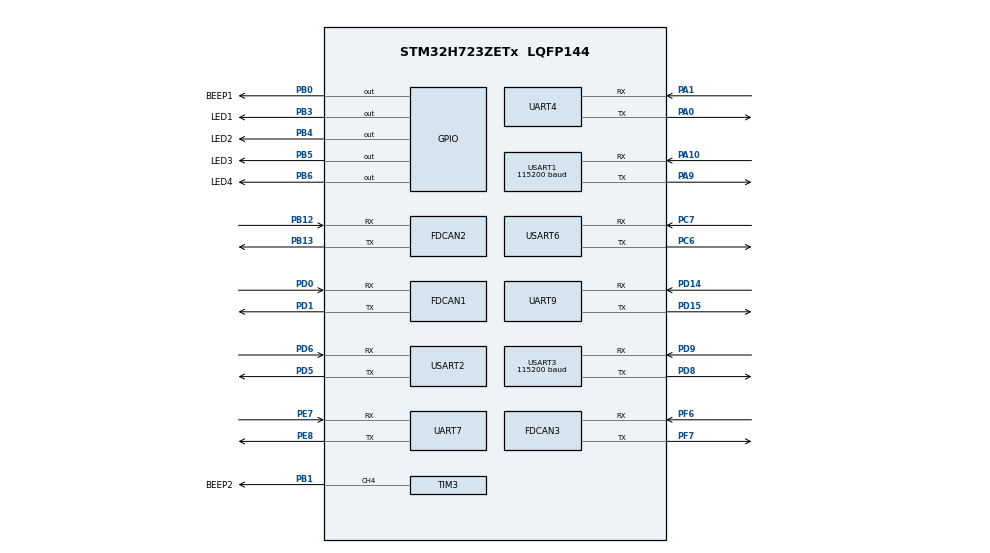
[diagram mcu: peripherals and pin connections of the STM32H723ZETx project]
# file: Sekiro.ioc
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CORTEX_M7.AccessPermission_S-Cortex_Memory_Protection_Unit_Region1_Settings_S=MPU_REGION_PRIV_RO
CORTEX_M7.AccessPermission_S-Cortex_Memory_Protection_Unit_Region2_Settings_S=MPU_REGION_FULL_ACCESS
CORTEX_M7.AccessPermission_Spec=MPU_REGION_FULL_ACCESS
CORTEX_M7.BaseAddress_S-Cortex_Memory_Protection_Unit_Region1_Settings_S=0x08000000
CORTEX_M7.BaseAddress_S-Cortex_Memory_Protection_Unit_Region2_Settings_S=0x30000000
CORTEX_M7.BaseAddress_Spec=0x24000000
CORTEX_M7.CPU_DCache=Enabled
CORTEX_M7.CPU_ICache=Enabled
CORTEX_M7.DisableExec_Spec=MPU_INSTRUCTION_ACCESS_ENABLE
CORTEX_M7.Enable_S-Cortex_Memory_Protection_Unit_Region1_Settings_S=MPU_REGION_ENABLE
CORTEX_M7.Enable_S-Cortex_Memory_Protection_Unit_Region2_Settings_S=MPU_REGION_ENABLE
CORTEX_M7.IsBufferable_Spec=MPU_ACCESS_BUFFERABLE
CORTEX_M7.IsCacheable_S-Cortex_Memory_Protection_Unit_Region1_Settings_S=MPU_ACCESS_CACHEABLE
CORTEX_M7.IsCacheable_S-Cortex_Memory_Protection_Unit_Region2_Settings_S=MPU_ACCESS_CACHEABLE
CORTEX_M7.IsCacheable_Spec=MPU_ACCESS_CACHEABLE
CORTEX_M7.IsShareable_Spec=MPU_ACCESS_NOT_SHAREABLE
CORTEX_M7.Number_S-Cortex_Memory_Protection_Unit_Region2_Settings_S=MPU_REGION_NUMBER2
CORTEX_M7.Number_S-Cortex_Memory_Protection_Unit_Region3_Settings_S=MPU_REGION_NUMBER3
CORTEX_M7.Number_S-Cortex_Memory_Protection_Unit_Region4_Settings_S=MPU_REGION_NUMBER4
CORTEX_M7.Size_S-Cortex_Memory_Protection_Unit_Region1_Settings_S=MPU_REGION_SIZE_512KB
CORTEX_M7.Size_S-Cortex_Memory_Protection_Unit_Region2_Settings_S=MPU_REGION_SIZE_512MB
CORTEX_M7.Size_Spec=MPU_REGION_SIZE_128KB
CORTEX_M7.SubRegionDisable_S-Cortex_Memory_Protection_Unit_Region2_Settings_S=0xFA
CORTEX_M7.SubRegionDisable_Spec=0
CORTEX_M7.TypeExtField_Spec=MPU_TEX_LEVEL1
CORTEX_M7.default_mode_Activation=1
Dma.Request0=USART3_RX
Dma.Request1=USART3_TX
Dma.Request2=USART2_RX
Dma.Request3=USART2_TX
Dma.Request4=USART6_RX
Dma.Request5=USART6_TX
Dma.Request6=USART1_RX
Dma.Request7=USART1_TX
Dma.Request8=UART9_TX
Dma.Request9=UART9_RX
Dma.UART9_RX.9.Direction=DMA_PERIPH_TO_MEMORY
Dma.UART9_RX.9.EventEnable=DISABLE
Dma.UART9_RX.9.FIFOMode=DMA_FIFOMODE_DISABLE
Dma.UART9_RX.9.Instance=DMA2_Stream1
Dma.UART9_RX.9.MemDataAlignment=DMA_MDATAALIGN_BYTE
Dma.UART9_RX.9.MemInc=DMA_MINC_ENABLE
Dma.UART9_RX.9.Mode=DMA_NORMAL
Dma.UART9_RX.9.PeriphDataAlignment=DMA_PDATAALIGN_BYTE
Dma.UART9_RX.9.PeriphInc=DMA_PINC_DISABLE
Dma.UART9_RX.9.Polarity=HAL_DMAMUX_REQ_GEN_RISING
Dma.UART9_RX.9.Priority=DMA_PRIORITY_VERY_HIGH
Dma.UART9_RX.9.RequestNumber=1
Dma.UART9_RX.9.SignalID=NONE
Dma.UART9_RX.9.SyncEnable=DISABLE
Dma.UART9_RX.9.SyncPolarity=HAL_DMAMUX_SYNC_NO_EVENT
Dma.UART9_RX.9.SyncRequestNumber=1
Dma.UART9_RX.9.SyncSignalID=NONE
Dma.UART9_TX.8.Direction=DMA_MEMORY_TO_PERIPH
Dma.UART9_TX.8.EventEnable=DISABLE
Dma.UART9_TX.8.FIFOMode=DMA_FIFOMODE_DISABLE
Dma.UART9_TX.8.Instance=DMA2_Stream0
Dma.UART9_TX.8.MemDataAlignment=DMA_MDATAALIGN_BYTE
Dma.UART9_TX.8.MemInc=DMA_MINC_ENABLE
Dma.UART9_TX.8.Mode=DMA_NORMAL
Dma.UART9_TX.8.PeriphDataAlignment=DMA_PDATAALIGN_BYTE
Dma.UART9_TX.8.PeriphInc=DMA_PINC_DISABLE
Dma.UART9_TX.8.Polarity=HAL_DMAMUX_REQ_GEN_RISING
Dma.UART9_TX.8.Priority=DMA_PRIORITY_VERY_HIGH
Dma.UART9_TX.8.RequestNumber=1
Dma.UART9_TX.8.SignalID=NONE
Dma.UART9_TX.8.SyncEnable=DISABLE
Dma.UART9_TX.8.SyncPolarity=HAL_DMAMUX_SYNC_NO_EVENT
Dma.UART9_TX.8.SyncRequestNumber=1
Dma.UART9_TX.8.SyncSignalID=NONE
Dma.USART1_RX.6.Direction=DMA_PERIPH_TO_MEMORY
Dma.USART1_RX.6.EventEnable=DISABLE
Dma.USART1_RX.6.FIFOMode=DMA_FIFOMODE_DISABLE
Dma.USART1_RX.6.Instance=DMA1_Stream4
Dma.USART1_RX.6.MemDataAlignment=DMA_MDATAALIGN_BYTE
Dma.USART1_RX.6.MemInc=DMA_MINC_ENABLE
Dma.USART1_RX.6.Mode=DMA_CIRCULAR
Dma.USART1_RX.6.PeriphDataAlignment=DMA_PDATAALIGN_BYTE
Dma.USART1_RX.6.PeriphInc=DMA_PINC_DISABLE
Dma.USART1_RX.6.Polarity=HAL_DMAMUX_REQ_GEN_RISING
Dma.USART1_RX.6.Priority=DMA_PRIORITY_VERY_HIGH
Dma.USART1_RX.6.RequestNumber=1
Dma.USART1_RX.6.SignalID=NONE
Dma.USART1_RX.6.SyncEnable=DISABLE
Dma.USART1_RX.6.SyncPolarity=HAL_DMAMUX_SYNC_NO_EVENT
Dma.USART1_RX.6.SyncRequestNumber=1
Dma.USART1_RX.6.SyncSignalID=NONE
Dma.USART1_TX.7.Direction=DMA_MEMORY_TO_PERIPH
Dma.USART1_TX.7.EventEnable=DISABLE
Dma.USART1_TX.7.FIFOMode=DMA_FIFOMODE_DISABLE
Dma.USART1_TX.7.Instance=DMA1_Stream5
Dma.USART1_TX.7.MemDataAlignment=DMA_MDATAALIGN_BYTE
Dma.USART1_TX.7.MemInc=DMA_MINC_ENABLE
Dma.USART1_TX.7.Mode=DMA_NORMAL
Dma.USART1_TX.7.PeriphDataAlignment=DMA_PDATAALIGN_BYTE
Dma.USART1_TX.7.PeriphInc=DMA_PINC_DISABLE
Dma.USART1_TX.7.Polarity=HAL_DMAMUX_REQ_GEN_RISING
Dma.USART1_TX.7.Priority=DMA_PRIORITY_VERY_HIGH
Dma.USART1_TX.7.RequestNumber=1
Dma.USART1_TX.7.SignalID=NONE
Dma.USART1_TX.7.SyncEnable=DISABLE
Dma.USART1_TX.7.SyncPolarity=HAL_DMAMUX_SYNC_NO_EVENT
Dma.USART1_TX.7.SyncRequestNumber=1
Dma.USART1_TX.7.SyncSignalID=NONE
Dma.USART2_RX.2.Direction=DMA_PERIPH_TO_MEMORY
Dma.USART2_RX.2.EventEnable=DISABLE
Dma.USART2_RX.2.FIFOMode=DMA_FIFOMODE_DISABLE
Dma.USART2_RX.2.Instance=DMA1_Stream2
Dma.USART2_RX.2.MemDataAlignment=DMA_MDATAALIGN_BYTE
Dma.USART2_RX.2.MemInc=DMA_MINC_ENABLE
Dma.USART2_RX.2.Mode=DMA_NORMAL
Dma.USART2_RX.2.PeriphDataAlignment=DMA_PDATAALIGN_BYTE
Dma.USART2_RX.2.PeriphInc=DMA_PINC_DISABLE
Dma.USART2_RX.2.Polarity=HAL_DMAMUX_REQ_GEN_RISING
Dma.USART2_RX.2.Priority=DMA_PRIORITY_VERY_HIGH
Dma.USART2_RX.2.RequestNumber=1
Dma.USART2_RX.2.SignalID=NONE
Dma.USART2_RX.2.SyncEnable=DISABLE
Dma.USART2_RX.2.SyncPolarity=HAL_DMAMUX_SYNC_NO_EVENT
Dma.USART2_RX.2.SyncRequestNumber=1
Dma.USART2_RX.2.SyncSignalID=NONE
Dma.USART2_TX.3.Direction=DMA_MEMORY_TO_PERIPH
Dma.USART2_TX.3.EventEnable=DISABLE
Dma.USART2_TX.3.FIFOMode=DMA_FIFOMODE_DISABLE
Dma.USART2_TX.3.Instance=DMA1_Stream3
Dma.USART2_TX.3.MemDataAlignment=DMA_MDATAALIGN_BYTE
Dma.USART2_TX.3.MemInc=DMA_MINC_ENABLE
Dma.USART2_TX.3.Mode=DMA_NORMAL
Dma.USART2_TX.3.PeriphDataAlignment=DMA_PDATAALIGN_BYTE
Dma.USART2_TX.3.PeriphInc=DMA_PINC_DISABLE
Dma.USART2_TX.3.Polarity=HAL_DMAMUX_REQ_GEN_RISING
Dma.USART2_TX.3.Priority=DMA_PRIORITY_VERY_HIGH
Dma.USART2_TX.3.RequestNumber=1
Dma.USART2_TX.3.SignalID=NONE
Dma.USART2_TX.3.SyncEnable=DISABLE
Dma.USART2_TX.3.SyncPolarity=HAL_DMAMUX_SYNC_NO_EVENT
Dma.USART2_TX.3.SyncRequestNumber=1
Dma.USART2_TX.3.SyncSignalID=NONE
Dma.USART3_RX.0.Direction=DMA_PERIPH_TO_MEMORY
Dma.USART3_RX.0.EventEnable=DISABLE
Dma.USART3_RX.0.FIFOMode=DMA_FIFOMODE_DISABLE
Dma.USART3_RX.0.Instance=DMA1_Stream0
Dma.USART3_RX.0.MemDataAlignment=DMA_MDATAALIGN_BYTE
Dma.USART3_RX.0.MemInc=DMA_MINC_ENABLE
Dma.USART3_RX.0.Mode=DMA_NORMAL
Dma.USART3_RX.0.PeriphDataAlignment=DMA_PDATAALIGN_BYTE
Dma.USART3_RX.0.PeriphInc=DMA_PINC_DISABLE
Dma.USART3_RX.0.Polarity=HAL_DMAMUX_REQ_GEN_RISING
Dma.USART3_RX.0.Priority=DMA_PRIORITY_VERY_HIGH
Dma.USART3_RX.0.RequestNumber=1
Dma.USART3_RX.0.SignalID=NONE
Dma.USART3_RX.0.SyncEnable=DISABLE
Dma.USART3_RX.0.SyncPolarity=HAL_DMAMUX_SYNC_NO_EVENT
Dma.USART3_RX.0.SyncRequestNumber=1
Dma.USART3_RX.0.SyncSignalID=NONE
Dma.USART3_TX.1.Direction=DMA_MEMORY_TO_PERIPH
Dma.USART3_TX.1.EventEnable=DISABLE
Dma.USART3_TX.1.FIFOMode=DMA_FIFOMODE_DISABLE
Dma.USART3_TX.1.Instance=DMA1_Stream1
Dma.USART3_TX.1.MemDataAlignment=DMA_MDATAALIGN_BYTE
Dma.USART3_TX.1.MemInc=DMA_MINC_ENABLE
Dma.USART3_TX.1.Mode=DMA_NORMAL
Dma.USART3_TX.1.PeriphDataAlignment=DMA_PDATAALIGN_BYTE
Dma.USART3_TX.1.PeriphInc=DMA_PINC_DISABLE
Dma.USART3_TX.1.Polarity=HAL_DMAMUX_REQ_GEN_RISING
Dma.USART3_TX.1.Priority=DMA_PRIORITY_VERY_HIGH
Dma.USART3_TX.1.RequestNumber=1
Dma.USART3_TX.1.SignalID=NONE
Dma.USART3_TX.1.SyncEnable=DISABLE
Dma.USART3_TX.1.SyncPolarity=HAL_DMAMUX_SYNC_NO_EVENT
Dma.USART3_TX.1.SyncRequestNumber=1
Dma.USART3_TX.1.SyncSignalID=NONE
Dma.USART6_RX.4.Direction=DMA_PERIPH_TO_MEMORY
Dma.USART6_RX.4.EventEnable=DISABLE
Dma.USART6_RX.4.FIFOMode=DMA_FIFOMODE_DISABLE
Dma.USART6_RX.4.Instance=DMA1_Stream6
Dma.USART6_RX.4.MemDataAlignment=DMA_MDATAALIGN_BYTE
Dma.USART6_RX.4.MemInc=DMA_MINC_ENABLE
Dma.USART6_RX.4.Mode=DMA_NORMAL
Dma.USART6_RX.4.PeriphDataAlignment=DMA_PDATAALIGN_BYTE
Dma.USART6_RX.4.PeriphInc=DMA_PINC_DISABLE
Dma.USART6_RX.4.Polarity=HAL_DMAMUX_REQ_GEN_RISING
Dma.USART6_RX.4.Priority=DMA_PRIORITY_VERY_HIGH
Dma.USART6_RX.4.RequestNumber=1
Dma.USART6_RX.4.SignalID=NONE
Dma.USART6_RX.4.SyncEnable=DISABLE
Dma.USART6_RX.4.SyncPolarity=HAL_DMAMUX_SYNC_NO_EVENT
Dma.USART6_RX.4.SyncRequestNumber=1
Dma.USART6_RX.4.SyncSignalID=NONE
Dma.USART6_TX.5.Direction=DMA_MEMORY_TO_PERIPH
Dma.USART6_TX.5.EventEnable=DISABLE
Dma.USART6_TX.5.FIFOMode=DMA_FIFOMODE_DISABLE
Dma.USART6_TX.5.Instance=DMA1_Stream7
Dma.USART6_TX.5.MemDataAlignment=DMA_MDATAALIGN_BYTE
Dma.USART6_TX.5.MemInc=DMA_MINC_ENABLE
Dma.USART6_TX.5.Mode=DMA_NORMAL
Dma.USART6_TX.5.PeriphDataAlignment=DMA_PDATAALIGN_BYTE
Dma.USART6_TX.5.PeriphInc=DMA_PINC_DISABLE
Dma.USART6_TX.5.Polarity=HAL_DMAMUX_REQ_GEN_RISING
Dma.USART6_TX.5.Priority=DMA_PRIORITY_VERY_HIGH
Dma.USART6_TX.5.RequestNumber=1
Dma.USART6_TX.5.SignalID=NONE
Dma.USART6_TX.5.SyncEnable=DISABLE
Dma.USART6_TX.5.SyncPolarity=HAL_DMAMUX_SYNC_NO_EVENT
Dma.USART6_TX.5.SyncRequestNumber=1
Dma.USART6_TX.5.SyncSignalID=NONE
FDCAN1.CalculateBaudRateNominal=1000000
FDCAN1.CalculateTimeBitNominal=1000
FDCAN1.CalculateTimeQuantumNominal=25.0
FDCAN1.DataSyncJumpWidth=5
FDCAN1.DataTimeSeg1=29
FDCAN1.DataTimeSeg2=10
FDCAN1.ExtFiltersNbr=16
FDCAN1.NominalPrescaler=1
FDCAN1.NominalSyncJumpWidth=5
FDCAN1.NominalTimeSeg1=29
FDCAN1.NominalTimeSeg2=10
FDCAN1.RxFifo0ElmtsNbr=12
FDCAN1.RxFifo1ElmtsNbr=12
FDCAN1.StdFiltersNbr=16
FDCAN1.TxBuffersNbr=16
FDCAN1.TxFifoQueueElmtsNbr=16
FDCAN2.CalculateBaudRateNominal=1000000
FDCAN2.CalculateTimeBitNominal=1000
FDCAN2.CalculateTimeQuantumNominal=25.0
FDCAN2.DataSyncJumpWidth=5
FDCAN2.DataTimeSeg1=29
FDCAN2.DataTimeSeg2=10
FDCAN2.ExtFiltersNbr=16
FDCAN2.MessageRAMOffset=850
FDCAN2.NominalPrescaler=1
FDCAN2.NominalSyncJumpWidth=5
FDCAN2.NominalTimeSeg1=29
FDCAN2.NominalTimeSeg2=10
FDCAN2.RxFifo0ElmtsNbr=12
FDCAN2.RxFifo1ElmtsNbr=12
FDCAN2.StdFiltersNbr=16
FDCAN2.TxBuffersNbr=16
FDCAN2.TxFifoQueueElmtsNbr=16
FDCAN3.CalculateBaudRateNominal=1000000
FDCAN3.CalculateTimeBitNominal=1000
FDCAN3.CalculateTimeQuantumNominal=25.0
FDCAN3.DataSyncJumpWidth=5
FDCAN3.DataTimeSeg1=29
FDCAN3.DataTimeSeg2=10
FDCAN3.ExtFiltersNbr=16
FDCAN3.MessageRAMOffset=1700
FDCAN3.NominalPrescaler=1
FDCAN3.NominalSyncJumpWidth=5
FDCAN3.NominalTimeSeg1=29
FDCAN3.NominalTimeSeg2=10
FDCAN3.RxFifo0ElmtsNbr=12
FDCAN3.RxFifo1ElmtsNbr=12
FDCAN3.StdFiltersNbr=16
FDCAN3.TxBuffersNbr=16
FDCAN3.TxFifoQueueElmtsNbr=16
FREERTOS.Tasks01=defaultTask,8,128,StartDefaultTask,As weak,NULL,Dynamic,NULL,NULL;TaskUsart,40,128,TaskUart,As weak,NULL,Dynamic,NULL,NULL;Taskchassis,47,256,TaskChassis,As weak,NULL,Dynamic,NULL,NULL;Sekirotask,47,512,SekiroTask,As weak,NULL,Dynamic,NULL,NULL;Test,8,128,Testtask,As weak,NULL,Dynamic,NULL,NULL;TaskTraj,48,2048,TaskTrajctory,As weak,NULL,Dynamic,NULL,NULL
Mcu.Family=STM32H7
Mcu.Name=STM32H723ZETx
Mcu.Package=LQFP144
NVIC.DMA1_Stream0_IRQn=true\:5\:0\:false\:false\:true\:true\:false\:true\:true
NVIC.DMA1_Stream1_IRQn=true\:5\:0\:false\:false\:true\:true\:false\:true\:true
NVIC.DMA1_Stream2_IRQn=true\:5\:0\:false\:false\:true\:true\:false\:true\:true
NVIC.DMA1_Stream3_IRQn=true\:5\:0\:false\:false\:true\:true\:false\:true\:true
NVIC.DMA1_Stream4_IRQn=true\:5\:0\:false\:false\:true\:true\:false\:true\:true
NVIC.DMA1_Stream5_IRQn=true\:5\:0\:false\:false\:true\:true\:false\:true\:true
NVIC.DMA1_Stream6_IRQn=true\:5\:0\:false\:false\:true\:true\:false\:true\:true
NVIC.DMA1_Stream7_IRQn=true\:5\:0\:false\:false\:true\:true\:false\:true\:true
NVIC.DMA2_Stream0_IRQn=true\:5\:0\:false\:false\:true\:true\:false\:true\:true
NVIC.DMA2_Stream1_IRQn=true\:5\:0\:false\:false\:true\:true\:false\:true\:true
NVIC.FDCAN1_IT0_IRQn=true\:5\:0\:false\:false\:true\:true\:true\:true\:true
NVIC.FDCAN1_IT1_IRQn=true\:5\:0\:false\:false\:true\:true\:true\:true\:true
NVIC.FDCAN2_IT0_IRQn=true\:5\:0\:false\:false\:true\:true\:true\:true\:true
NVIC.FDCAN2_IT1_IRQn=true\:5\:0\:false\:false\:true\:true\:true\:true\:true
NVIC.FDCAN3_IT0_IRQn=true\:5\:0\:false\:false\:true\:true\:true\:true\:true
NVIC.FDCAN3_IT1_IRQn=true\:5\:0\:false\:false\:true\:true\:true\:true\:true
NVIC.PriorityGroup=NVIC_PRIORITYGROUP_4
NVIC.TIM1_UP_IRQn=true\:15\:0\:false\:false\:true\:false\:false\:true\:true
NVIC.TIM2_IRQn=true\:5\:0\:false\:false\:true\:true\:true\:true\:true
NVIC.TIM4_IRQn=true\:5\:0\:false\:false\:true\:true\:true\:true\:true
NVIC.TIM5_IRQn=true\:5\:0\:false\:false\:true\:true\:true\:true\:true
NVIC.TimeBase=TIM1_UP_IRQn
NVIC.TimeBaseIP=TIM1
NVIC.UART4_IRQn=true\:5\:0\:false\:false\:true\:true\:true\:true\:true
NVIC.UART7_IRQn=true\:5\:0\:false\:false\:true\:true\:true\:true\:true
NVIC.UART9_IRQn=true\:5\:0\:false\:false\:true\:true\:true\:true\:true
NVIC.USART1_IRQn=true\:5\:0\:true\:false\:true\:true\:true\:true\:true
NVIC.USART2_IRQn=true\:5\:0\:false\:false\:true\:true\:true\:true\:true
NVIC.USART3_IRQn=true\:5\:0\:false\:false\:true\:true\:true\:true\:true
NVIC.USART6_IRQn=true\:5\:0\:false\:false\:true\:true\:true\:true\:true
PA0.Mode=Asynchronous
PA0.Signal=UART4_TX
PA1.Mode=Asynchronous
PA1.Signal=UART4_RX
PA10.Mode=Asynchronous
PA10.Signal=USART1_RX
PA13(JTMS/SWDIO).Mode=Serial_Wire
PA13(JTMS/SWDIO).Signal=DEBUG_JTMS-SWDIO
PA14(JTCK/SWCLK).Mode=Serial_Wire
PA14(JTCK/SWCLK).Signal=DEBUG_JTCK-SWCLK
PA9.Mode=Asynchronous
PA9.Signal=USART1_TX
PB0.GPIO_Label=BEEP1
PB0.GPIO_ModeDefaultOutputPP=GPIO_MODE_OUTPUT_PP
PB0.GPIO_PuPd=GPIO_PULLDOWN
PB0.GPIO_Speed=GPIO_SPEED_FREQ_VERY_HIGH
PB0.PinState=GPIO_PIN_SET
PB0.Signal=GPIO_Output
PB1.GPIO_Label=BEEP2
PB1.GPIO_PuPd=GPIO_PULLDOWN
PB1.GPIO_Speed=GPIO_SPEED_FREQ_VERY_HIGH
PB1.Signal=S_TIM3_CH4
PB12.GPIO_PuPd=GPIO_PULLDOWN
PB12.GPIO_Speed=GPIO_SPEED_FREQ_VERY_HIGH
PB12.Mode=FDCAN_Activate
PB12.Signal=FDCAN2_RX
PB13.GPIO_PuPd=GPIO_PULLDOWN
PB13.GPIO_Speed=GPIO_SPEED_FREQ_VERY_HIGH
PB13.Mode=FDCAN_Activate
PB13.Signal=FDCAN2_TX
PB3(JTDO/TRACESWO).GPIO_Label=LED1
PB3(JTDO/TRACESWO).GPIO_PuPd=GPIO_PULLDOWN
PB3(JTDO/TRACESWO).GPIO_Speed=GPIO_SPEED_FREQ_VERY_HIGH
PB3(JTDO/TRACESWO).PinState=GPIO_PIN_SET
PB3(JTDO/TRACESWO).Signal=GPIO_Output
PB4(NJTRST).GPIO_Label=LED2
PB4(NJTRST).GPIO_ModeDefaultOutputPP=GPIO_MODE_OUTPUT_PP
PB4(NJTRST).GPIO_PuPd=GPIO_PULLDOWN
PB4(NJTRST).GPIO_Speed=GPIO_SPEED_FREQ_VERY_HIGH
PB4(NJTRST).PinState=GPIO_PIN_SET
PB4(NJTRST).Signal=GPIO_Output
PB5.GPIO_Label=LED3
PB5.GPIO_ModeDefaultOutputPP=GPIO_MODE_OUTPUT_PP
PB5.GPIO_PuPd=GPIO_PULLDOWN
PB5.GPIO_Speed=GPIO_SPEED_FREQ_VERY_HIGH
PB5.PinState=GPIO_PIN_SET
PB5.Signal=GPIO_Output
PB6.GPIO_FM6=__NULL
PB6.GPIO_Label=LED4
PB6.GPIO_PuPd=GPIO_PULLDOWN
PB6.GPIO_Speed=GPIO_SPEED_FREQ_VERY_HIGH
PB6.PinState=GPIO_PIN_SET
PB6.Signal=GPIO_Output
PC6.Mode=Asynchronous
PC6.Signal=USART6_TX
PC7.Mode=Asynchronous
PC7.Signal=USART6_RX
PD0.GPIO_PuPd=GPIO_PULLDOWN
PD0.GPIO_Speed=GPIO_SPEED_FREQ_VERY_HIGH
PD0.Mode=FDCAN_Activate
PD0.Signal=FDCAN1_RX
PD1.GPIO_PuPd=GPIO_PULLDOWN
PD1.GPIO_Speed=GPIO_SPEED_FREQ_VERY_HIGH
PD1.Mode=FDCAN_Activate
PD1.Signal=FDCAN1_TX
PD14.Mode=Asynchronous
PD14.Signal=UART9_RX
PD15.Mode=Asynchronous
PD15.Signal=UART9_TX
PD5.GPIO_PuPd=GPIO_PULLDOWN
PD5.GPIO_Speed=GPIO_SPEED_FREQ_VERY_HIGH
PD5.Mode=Asynchronous
PD5.Signal=USART2_TX
PD6.GPIO_PuPd=GPIO_PULLDOWN
PD6.GPIO_Speed=GPIO_SPEED_FREQ_VERY_HIGH
PD6.Mode=Asynchronous
PD6.Signal=USART2_RX
PD8.GPIO_PuPd=GPIO_PULLDOWN
PD8.GPIO_Speed=GPIO_SPEED_FREQ_VERY_HIGH
PD8.Mode=Asynchronous
PD8.Signal=USART3_TX
PD9.GPIO_PuPd=GPIO_PULLDOWN
PD9.GPIO_Speed=GPIO_SPEED_FREQ_VERY_HIGH
PD9.Mode=Asynchronous
PD9.Signal=USART3_RX
PE7.Mode=Asynchronous
PE7.Signal=UART7_RX
PE8.Mode=Asynchronous
PE8.Signal=UART7_TX
PF6.GPIO_PuPd=GPIO_PULLDOWN
PF6.GPIO_Speed=GPIO_SPEED_FREQ_VERY_HIGH
PF6.Mode=FDCAN_Activate
PF6.Signal=FDCAN3_RX
PF7.GPIO_PuPd=GPIO_PULLDOWN
PF7.GPIO_Speed=GPIO_SPEED_FREQ_VERY_HIGH
PF7.Mode=FDCAN_Activate
PF7.Signal=FDCAN3_TX
PH0-OSC_IN.Mode=HSE-External-Oscillator
PH0-OSC_IN.Signal=RCC_OSC_IN
PH1-OSC_OUT.Mode=HSE-External-Oscillator
PH1-OSC_OUT.Signal=RCC_OSC_OUT
ProjectManager.HeapSize=0x1000
ProjectManager.StackSize=0x2000
ProjectManager.TargetToolchain=MDK-ARM V5.32
RCC.ADCFreq_Value=100000000
RCC.APB1Freq_Value=137500000
RCC.APB2Freq_Value=137500000
RCC.APB3Freq_Value=137500000
RCC.APB4Freq_Value=137500000
RCC.CortexFreq_Value=550000000
RCC.D1PPRE=RCC_APB3_DIV2
RCC.D2PPRE1=RCC_APB1_DIV2
RCC.D2PPRE2=RCC_APB2_DIV2
RCC.D3PPRE=RCC_APB4_DIV2
RCC.DIVM1=2
RCC.DIVM2=2
RCC.DIVN1=44
RCC.DIVN2=16
RCC.DIVP1=1
RCC.DIVQ2=5
RCC.FDCANCLockSelection=RCC_FDCANCLKSOURCE_PLL2
RCC.HCLKFreq_Value=275000000
RCC.HPRE=RCC_HCLK_DIV2
RCC.PLL2FRACN=0
RCC.PLLFRACN=0
RCC.PLLSourceVirtual=RCC_PLLSOURCE_HSE
RCC.SYSCLKFreq_VALUE=550000000
RCC.SYSCLKSource=RCC_SYSCLKSOURCE_PLLCLK
RCC.USBFreq_Value=275000000
SH.S_TIM3_CH4.0=TIM3_CH4,PWM Generation4 CH4
STMicroelectronics.X-CUBE-ALGOBUILD.1.4.0.LibraryCcDSPOoLibraryJjDSPOoLibrary=true
TIM2.Period=999
TIM2.Prescaler=274
TIM3.Channel-PWM\ Generation4\ CH4=TIM_CHANNEL_4
TIM3.Period=999
TIM3.Prescaler=274
TIM3.Pulse-PWM\ Generation4\ CH4=499
TIM4.Period=999
TIM4.Prescaler=274
TIM5.Period=999
TIM5.Prescaler=274
USART1.BaudRate=115200
USART1.FIFOMode=FIFOMODE_ENABLE
USART1.RXFIFOThreshold=RXFIFO_THRESHOLD_HALFFULL
USART1.VirtualMode-Asynchronous=VM_ASYNC
USART2.VirtualMode-Asynchronous=VM_ASYNC
USART3.BaudRate=115200
USART3.VirtualMode-Asynchronous=VM_ASYNC
USART6.VirtualMode-Asynchronous=VM_ASYNC
VP_FREERTOS_VS_CMSIS_V2.Mode=CMSIS_V2
VP_MEMORYMAP_VS_MEMORYMAP.Mode=CurAppReg
VP_STMicroelectronics.X-CUBE-ALGOBUILD_VS_DSPOoLibraryJjLibrary_1.4.0_1.4.0.Mode=DSPOoLibraryJjLibrary
VP_SYS_VS_tim1.Mode=TIM1
VP_TIM2_VS_ClockSourceINT.Mode=Internal
VP_TIM3_VS_ClockSourceINT.Mode=Internal
VP_TIM4_VS_ClockSourceINT.Mode=Internal
VP_TIM5_VS_ClockSourceINT.Mode=Internal
board=custom

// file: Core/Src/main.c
/* USER CODE BEGIN Header */
/**
  ******************************************************************************
  * @file           : main.c
  * @brief          : Main program body
  ******************************************************************************
  * @attention
  *
  * Copyright (c) 2025 STMicroelectronics.
  * All rights reserved.
  *
  * This software is licensed under terms that can be found in the LICENSE file
  * in the root directory of this software component.
  * If no LICENSE file comes with this software, it is provided AS-IS.
  *
  ******************************************************************************
  */
/* USER CODE END Header */
#include "main.h"
#include "FreeRTOS.h"
#include "cmsis_os2.h"
#include "dma.h"
#include "fdcan.h"
#include "tim.h"
#include "usart.h"
#include "gpio.h"

/* USER CODE BEGIN Includes */
#include "Sekiro.h"
//#include "EventRecorder.h"
/* USER CODE END Includes */

void SystemClock_Config(void);
void PeriphCommonClock_Config(void);
static void MPU_Config(void);
void MX_FREERTOS_Init(void);

int main(void)
{

  /* USER CODE BEGIN 1 */

	uint32_t *SourceAddr = (uint32_t *)FLASH_BANK1_BASE;
	uint32_t *DestAddr = (uint32_t *)D1_DTCMRAM_BASE;
	memcpy(DestAddr, SourceAddr, 0x400);
	SCB->VTOR = D1_DTCMRAM_BASE; //向量表重定向

//	EventRecorderInitialize(EventRecordAll, 1U);
//	EventRecorderStart();

  /* USER CODE END 1 */

  /* MPU Configuration--------------------------------------------------------*/
  MPU_Config();

  /* Enable the CPU Cache */

  /* Enable I-Cache---------------------------------------------------------*/
  SCB_EnableICache();

  /* Enable D-Cache---------------------------------------------------------*/
  SCB_EnableDCache();

  /* MCU Configuration--------------------------------------------------------*/

  /* Reset of all peripherals, Initializes the Flash interface and the Systick. */
  HAL_Init();

  /* Configure the system clock */
  SystemClock_Config();

  /* Configure the peripherals common clocks */
  PeriphCommonClock_Config();

  /* Initialize all configured peripherals */
  MX_GPIO_Init();
  MX_DMA_Init();
  MX_TIM2_Init();
  MX_TIM3_Init();
  MX_FDCAN1_Init();
  MX_FDCAN2_Init();
  MX_FDCAN3_Init();
  MX_TIM4_Init();
  MX_TIM5_Init();
  MX_USART1_UART_Init();
  MX_USART3_UART_Init();
  MX_USART2_UART_Init();
  MX_USART6_UART_Init();
  MX_UART4_Init();
  MX_UART7_Init();
  MX_UART9_Init();
  /* USER CODE BEGIN 2 */
  Program_Init();
  /* USER CODE END 2 */

  /* Init scheduler */
  osKernelInitialize();  /* Call init function for freertos objects (in cmsis_os2.c) */
  MX_FREERTOS_Init();

  /* Start scheduler */
  osKernelStart();

  /* We should never get here as control is now taken by the scheduler */

  /* Infinite loop */
  while (1)
  {

  }
}

void SystemClock_Config(void)
{
  RCC_OscInitTypeDef RCC_OscInitStruct = {0};
  RCC_ClkInitTypeDef RCC_ClkInitStruct = {0};

  /** Supply configuration update enable
  */
  HAL_PWREx_ConfigSupply(PWR_LDO_SUPPLY);

  /** Configure the main internal regulator output voltage
  */
  __HAL_PWR_VOLTAGESCALING_CONFIG(PWR_REGULATOR_VOLTAGE_SCALE0);

  while(!__HAL_PWR_GET_FLAG(PWR_FLAG_VOSRDY)) {}

  /** Initializes the RCC Oscillators according to the specified parameters
  * in the RCC_OscInitTypeDef structure.
  */
  RCC_OscInitStruct.OscillatorType = RCC_OSCILLATORTYPE_HSE;
  RCC_OscInitStruct.HSEState = RCC_HSE_ON;
  RCC_OscInitStruct.PLL.PLLState = RCC_PLL_ON;
  RCC_OscInitStruct.PLL.PLLSource = RCC_PLLSOURCE_HSE;
  RCC_OscInitStruct.PLL.PLLM = 2;
  RCC_OscInitStruct.PLL.PLLN = 44;
  RCC_OscInitStruct.PLL.PLLP = 1;
  RCC_OscInitStruct.PLL.PLLQ = 2;
  RCC_OscInitStruct.PLL.PLLR = 2;
  RCC_OscInitStruct.PLL.PLLRGE = RCC_PLL1VCIRANGE_3;
  RCC_OscInitStruct.PLL.PLLVCOSEL = RCC_PLL1VCOWIDE;
  RCC_OscInitStruct.PLL.PLLFRACN = 0;
  if (HAL_RCC_OscConfig(&RCC_OscInitStruct) != HAL_OK)
  {
    Error_Handler();
  }

  /** Initializes the CPU, AHB and APB buses clocks
  */
  RCC_ClkInitStruct.ClockType = RCC_CLOCKTYPE_HCLK|RCC_CLOCKTYPE_SYSCLK
                              |RCC_CLOCKTYPE_PCLK1|RCC_CLOCKTYPE_PCLK2
                              |RCC_CLOCKTYPE_D3PCLK1|RCC_CLOCKTYPE_D1PCLK1;
  RCC_ClkInitStruct.SYSCLKSource = RCC_SYSCLKSOURCE_PLLCLK;
  RCC_ClkInitStruct.SYSCLKDivider = RCC_SYSCLK_DIV1;
  RCC_ClkInitStruct.AHBCLKDivider = RCC_HCLK_DIV2;
  RCC_ClkInitStruct.APB3CLKDivider = RCC_APB3_DIV2;
  RCC_ClkInitStruct.APB1CLKDivider = RCC_APB1_DIV2;
  RCC_ClkInitStruct.APB2CLKDivider = RCC_APB2_DIV2;
  RCC_ClkInitStruct.APB4CLKDivider = RCC_APB4_DIV2;

  if (HAL_RCC_ClockConfig(&RCC_ClkInitStruct, FLASH_LATENCY_3) != HAL_OK)
  {
    Error_Handler();
  }
}

void PeriphCommonClock_Config(void)
{
  RCC_PeriphCLKInitTypeDef PeriphClkInitStruct = {0};

  /** Initializes the peripherals clock
  */
  PeriphClkInitStruct.PeriphClockSelection = RCC_PERIPHCLK_FDCAN;
  PeriphClkInitStruct.PLL2.PLL2M = 2;
  PeriphClkInitStruct.PLL2.PLL2N = 16;
  PeriphClkInitStruct.PLL2.PLL2P = 2;
  PeriphClkInitStruct.PLL2.PLL2Q = 5;
  PeriphClkInitStruct.PLL2.PLL2R = 2;
  PeriphClkInitStruct.PLL2.PLL2RGE = RCC_PLL2VCIRANGE_3;
  PeriphClkInitStruct.PLL2.PLL2VCOSEL = RCC_PLL2VCOWIDE;
  PeriphClkInitStruct.PLL2.PLL2FRACN = 0;
  PeriphClkInitStruct.FdcanClockSelection = RCC_FDCANCLKSOURCE_PLL2;
  if (HAL_RCCEx_PeriphCLKConfig(&PeriphClkInitStruct) != HAL_OK)
  {
    Error_Handler();
  }
}

 /* MPU Configuration */

void MPU_Config(void)
{
  MPU_Region_InitTypeDef MPU_InitStruct = {0};

  /* Disables the MPU */
  HAL_MPU_Disable();

  /** Initializes and configures the Region and the memory to be protected
  */
  MPU_InitStruct.Enable = MPU_REGION_ENABLE;
  MPU_InitStruct.Number = MPU_REGION_NUMBER0;
  MPU_InitStruct.BaseAddress = 0x24000000;
  MPU_InitStruct.Size = MPU_REGION_SIZE_128KB;
  MPU_InitStruct.SubRegionDisable = 0;
  MPU_InitStruct.TypeExtField = MPU_TEX_LEVEL1;
  MPU_InitStruct.AccessPermission = MPU_REGION_FULL_ACCESS;
  MPU_InitStruct.DisableExec = MPU_INSTRUCTION_ACCESS_ENABLE;
  MPU_InitStruct.IsShareable = MPU_ACCESS_NOT_SHAREABLE;
  MPU_InitStruct.IsCacheable = MPU_ACCESS_CACHEABLE;
  MPU_InitStruct.IsBufferable = MPU_ACCESS_BUFFERABLE;

  HAL_MPU_ConfigRegion(&MPU_InitStruct);

  /** Initializes and configures the Region and the memory to be protected
  */
  MPU_InitStruct.Number = MPU_REGION_NUMBER1;
  MPU_InitStruct.BaseAddress = 0x08000000;
  MPU_InitStruct.Size = MPU_REGION_SIZE_512KB;
  MPU_InitStruct.SubRegionDisable = 0x0;
  MPU_InitStruct.TypeExtField = MPU_TEX_LEVEL0;
  MPU_InitStruct.AccessPermission = MPU_REGION_PRIV_RO;
  MPU_InitStruct.IsBufferable = MPU_ACCESS_NOT_BUFFERABLE;

  HAL_MPU_ConfigRegion(&MPU_InitStruct);

  /** Initializes and configures the Region and the memory to be protected
  */
  MPU_InitStruct.Number = MPU_REGION_NUMBER2;
  MPU_InitStruct.BaseAddress = 0x30000000;
  MPU_InitStruct.Size = MPU_REGION_SIZE_512MB;
  MPU_InitStruct.SubRegionDisable = 0xFA;
  MPU_InitStruct.AccessPermission = MPU_REGION_FULL_ACCESS;

  HAL_MPU_ConfigRegion(&MPU_InitStruct);
  /* Enables the MPU */
  HAL_MPU_Enable(MPU_PRIVILEGED_DEFAULT);

}

void HAL_TIM_PeriodElapsedCallback(TIM_HandleTypeDef *htim)
{
  if (htim->Instance == TIM1)
  {
    HAL_IncTick();
  }
  /* USER CODE BEGIN Callback 1 */
	TIM_PeriodElapsedCallback(htim);
  /* USER CODE END Callback 1 */
}

void Error_Handler(void)
{
  __disable_irq();
  while (1)
  {
  }
}

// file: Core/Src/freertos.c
/* USER CODE BEGIN Header */
/**
  ******************************************************************************
  * File Name          : freertos.c
  * Description        : Code for freertos applications
  ******************************************************************************
  * @attention
  *
  * Copyright (c) 2025 STMicroelectronics.
  * All rights reserved.
  *
  * This software is licensed under terms that can be found in the LICENSE file
  * in the root directory of this software component.
  * If no LICENSE file comes with this software, it is provided AS-IS.
  *
  ******************************************************************************
  */
/* USER CODE END Header */

#include "FreeRTOS.h"
#include "task.h"
#include "main.h"
#include "FreeRTOS.h"
#include "cmsis_os2.h"

/* Definitions for defaultTask */
osThreadId_t defaultTaskHandle;
const osThreadAttr_t defaultTask_attributes = {
  .name = "defaultTask",
  .stack_size = 128 * 4,
  .priority = (osPriority_t) osPriorityLow,
};
/* Definitions for TaskUsart */
osThreadId_t TaskUsartHandle;
const osThreadAttr_t TaskUsart_attributes = {
  .name = "TaskUsart",
  .stack_size = 128 * 4,
  .priority = (osPriority_t) osPriorityHigh,
};
/* Definitions for Taskchassis */
osThreadId_t TaskchassisHandle;
const osThreadAttr_t Taskchassis_attributes = {
  .name = "Taskchassis",
  .stack_size = 256 * 4,
  .priority = (osPriority_t) osPriorityHigh7,
};
/* Definitions for Sekirotask */
osThreadId_t SekirotaskHandle;
const osThreadAttr_t Sekirotask_attributes = {
  .name = "Sekirotask",
  .stack_size = 512 * 4,
  .priority = (osPriority_t) osPriorityHigh7,
};
/* Definitions for Test */
osThreadId_t TestHandle;
const osThreadAttr_t Test_attributes = {
  .name = "Test",
  .stack_size = 128 * 4,
  .priority = (osPriority_t) osPriorityLow,
};
/* Definitions for TaskTraj */
osThreadId_t TaskTrajHandle;
const osThreadAttr_t TaskTraj_attributes = {
  .name = "TaskTraj",
  .stack_size = 2048 * 4,
  .priority = (osPriority_t) osPriorityRealtime,
};

void StartDefaultTask(void *argument);
void TaskUart(void *argument);
void TaskChassis(void *argument);
void SekiroTask(void *argument);
void Testtask(void *argument);
void TaskTrajctory(void *argument);

void MX_FREERTOS_Init(void); /* (MISRA C 2004 rule 8.1) */

void MX_FREERTOS_Init(void) {

  /* Create the thread(s) */
  /* creation of defaultTask */
  defaultTaskHandle = osThreadNew(StartDefaultTask, NULL, &defaultTask_attributes);

  /* creation of TaskUsart */
  TaskUsartHandle = osThreadNew(TaskUart, NULL, &TaskUsart_attributes);

  /* creation of Taskchassis */
  TaskchassisHandle = osThreadNew(TaskChassis, NULL, &Taskchassis_attributes);

  /* creation of Sekirotask */
  SekirotaskHandle = osThreadNew(SekiroTask, NULL, &Sekirotask_attributes);

  /* creation of Test */
  TestHandle = osThreadNew(Testtask, NULL, &Test_attributes);

  /* creation of TaskTraj */
  TaskTrajHandle = osThreadNew(TaskTrajctory, NULL, &TaskTraj_attributes);

}

__weak void StartDefaultTask(void *argument)
{
  for(;;)
  {
    osDelay(1);
  }
}

__weak void TaskUart(void *argument)
{
  for(;;)
  {
    osDelay(1);
  }
}

__weak void TaskChassis(void *argument)
{
  for(;;)
  {
    osDelay(1);
  }
}

__weak void SekiroTask(void *argument)
{
  for(;;)
  {
    osDelay(1);
  }
}

__weak void Testtask(void *argument)
{
  for(;;)
  {
    osDelay(1);
  }
}

__weak void TaskTrajctory(void *argument)
{
  for(;;)
  {
    osDelay(1);
  }
}
